# GT32U2086 register map
Vendor: FPTTelecom
Registers are 32-bit, read-write, reset 0x0 unless marked. A register's access mark holds for its fields unless they carry their own. Offsets are from the block's base; [hi:lo] are bit positions.

## SPI0 — SPI0 - DTI SPI rev1.1, Register Description chapter 9. SPI0 : 0x440C0000 - 0x440CFFFF (64 KB)
Base 0x440C0000
Same registers: SPI1 0x50090000
0x00 TX — Transmit Register bit[31:0] DATA
  [31:0] DATA — Transmit data; the effective width is determined by CMDCONF.LEN in master mode
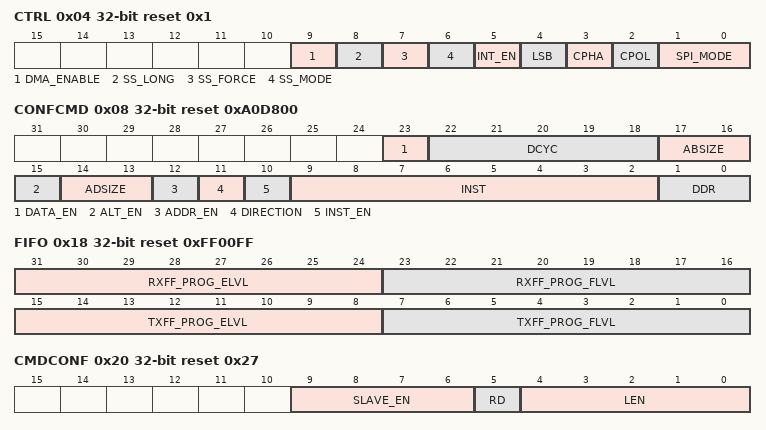
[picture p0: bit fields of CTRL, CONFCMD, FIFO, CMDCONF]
0x04 CTRL reset 0x1 — SPI Control Register bit[1:0] SPI_MODE | bit[2] CPOL | bit[3] CPHA | bit[4] LSB | bit[5] INT_EN | bit[6] SS_MODE | bit[7] SS_FORCE | bit[8] SS_LONG | bit[9] DMA_ENABLE
  [9] DMA_ENABLE — Globally enable the DMA interface (ctrl_dspi_modeable in rev1.1)
  [8] SS_LONG — Keep SS active until the TX FIFO is empty for long access sequences
  [7] SS_FORCE — In manual mode: 0=keep SS active, 1=allow SS release when conditions are met
  [6] SS_MODE — Master-mode SS control: 0=normal, 1=manual
  [5] INT_EN — Enable FIFO-status interrupt outputs
  [4] LSB — Bit order: 0=MSB first, 1=LSB first
  [3] CPHA — Clock phase: 0=sample on the first edge, 1=sample on the second edge
  [2] CPOL — SCLK idle level: 0=low, 1=high
  [1:0] SPI_MODE — 00=legacy slave, 01=legacy master, 10=extended DDR master; 11 reserved
0x08 CONFCMD reset 0xA0D800 — Extended DDR command configuration; unused in legacy SPI mode
  [23] DATA_EN — Enable data phase
  [22:18] DCYC — Extended-command dummy length, 0..31
  [17:16] ABSIZE — Alternate-byte size minus one byte, 0..3
  [15] ALT_EN — Enable alternate-byte phase
  [14:13] ADSIZE — Address size minus one byte, 0..3
  [12] ADDR_EN — Enable address phase
  [11] DIRECTION — 0=write, 1=read
  [10] INST_EN — Enable instruction phase
  [9:2] INST — Instruction byte
  [1:0] DDR — 00=SDR, 01=instruction SDR and remaining phases DDR, 11=DDR
0x0C DLR — Extended-mode data length register
  [31:0] DATA_LEN — Number of data bytes to send or receive
0x10 AR — Extended-mode command address register
  [31:0] ADDR — Command address
0x14 ABR — Extended-mode alternate-byte register
  [31:0] ALT_BYTE — Alternate-byte data
0x18 FIFO reset 0xFF00FF — FIFO Control Register bit[7:0] TXFF_PROG_FLVL | bit[15:8] TXFF_PROG_ELVL | bit[23:16] RXFF_PROG_FLVL | bit[31:24] RXFF_PROG_ELVL
  [31:24] RXFF_PROG_ELVL — Programmable RX FIFO empty threshold
  [23:16] RXFF_PROG_FLVL — Programmable RX FIFO full threshold
  [15:8] TXFF_PROG_ELVL — Programmable TX FIFO empty threshold
  [7:0] TXFF_PROG_FLVL — Programmable TX FIFO full threshold
0x1C CLK — Clock Register bit[15:0] DIV
  [15:0] DIV — SCLK period = 2 x (DIV + 1) x core-clock period
0x20 CMDCONF reset 0x27 — Command Configuration Register bit[4:0] LEN | bit[5] RD | bit[9:6] SLAVE_EN
  [9:6] SLAVE_EN — Select SS0..SS3 as one-hot in master mode
  [5] RD — Master: 1=store MISO data in the RX FIFO, 0=discard received data
  [4:0] LEN — Frame length minus 1; only 7/15/23/31 are supported, corresponding to 8/16/24/32 bits
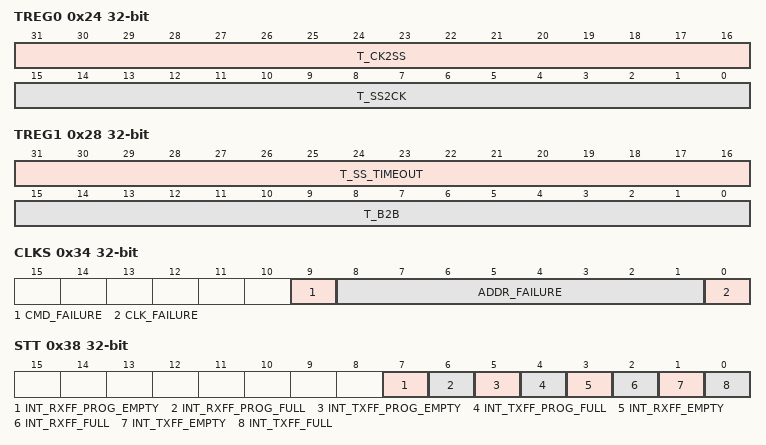
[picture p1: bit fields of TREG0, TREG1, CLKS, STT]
0x24 TREG0 — Timing Register 0 bit[15:0] T_SS2CK | bit[31:16] T_CK2SS
  [31:16] T_CK2SS — Number of cycles from stopping SCLK to SS deassertion
  [15:0] T_SS2CK — Number of cycles from SS assertion to SCLK generation
0x28 TREG1 — Timing Register 1 bit[15:0] T_B2B | bit[31:16] T_SS_TIMEOUT
  [31:16] T_SS_TIMEOUT — SS-active hold timeout; 0=disable the timeout function
  [15:0] T_B2B — Delay between data bytes in core-clock cycles, including bytes within a 16/24/32-bit word
0x2C TREG2 — Extended-mode timing register 2
  [15:0] T_CMD2CMD — Delay between extended DDR commands in core-clock cycles
0x30 RX ro — Receive Register bit[31:0] DATA
  [31:0] DATA — Receive data; the effective width is determined by CMDCONF.LEN in master mode
0x34 CLKS ro — Clock Status Register bit[0] CLK_FAILURE | bit[8:1] ADDR_FAILURE | bit[9] CMD_FAILURE
  [9] CMD_FAILURE — Failed command type: 0=write, 1=read
  [8:1] ADDR_FAILURE — Address of the first APB command affected by the clock failure
  [0] CLK_FAILURE — Core-clock stoppage detected
0x38 STT ro — Status Register bit[0] INT_TXFF_FULL | bit[1] INT_TXFF_EMPTY | bit[2] INT_RXFF_FULL | bit[3] INT_RXFF_EMPTY | bit[4] INT_TXFF_PROG_FULL | bit[5] INT_TXFF_PROG_EMPTY | bit[6] INT_RXFF_PROG_FULL | bit[7] INT_RXFF_PROG_EMPTY
  [7] INT_RXFF_PROG_EMPTY — RX FIFO reached the programmable-empty threshold
  [6] INT_RXFF_PROG_FULL — RX FIFO reached the programmable-full threshold
  [5] INT_TXFF_PROG_EMPTY — TX FIFO reached the programmable-empty threshold
  [4] INT_TXFF_PROG_FULL — TX FIFO reached the programmable-full threshold
  [3] INT_RXFF_EMPTY — RX FIFO empty
  [2] INT_RXFF_FULL — RX FIFO full
  [1] INT_TXFF_EMPTY — TX FIFO empty
  [0] INT_TXFF_FULL — TX FIFO full
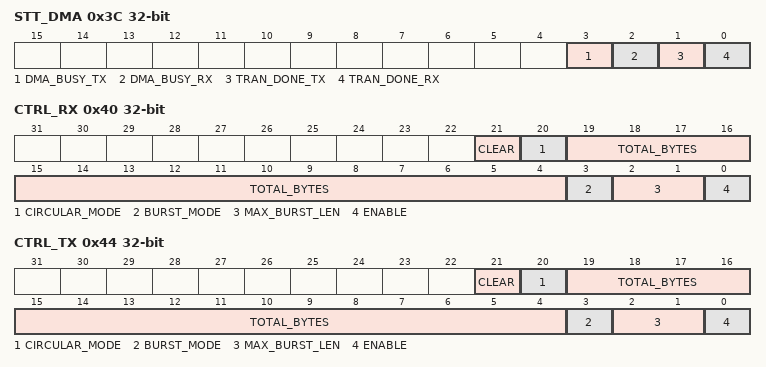
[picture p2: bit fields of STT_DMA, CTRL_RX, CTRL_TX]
0x3C STT_DMA ro — DMA Status Register bit[0] TRAN_DONE_RX | bit[1] TRAN_DONE_TX | bit[2] DMA_BUSY_RX | bit[3] DMA_BUSY_TX
  [3] DMA_BUSY_TX — Circular TX reconfiguration readiness: 1=allowed, 0=not yet allowed
  [2] DMA_BUSY_RX — Circular RX reconfiguration readiness: 1=allowed, 0=not yet allowed
  [1] TRAN_DONE_TX — DMA TX flag: 0=incomplete, 1=complete
  [0] TRAN_DONE_RX — DMA RX flag: 0=incomplete, 1=complete
0x40 CTRL_RX — DMA RX Control Register bit[0] ENABLE | bit[2:1] MAX_BURST_LEN | bit[3] BURST_MODE | bit[19:4] TOTAL_BYTES | bit[20] CIRCULAR_MODE | bit[21] CLEAR
  [21] CLEAR — Clear transfer-complete state and rearm one-shot configuration
  [20] CIRCULAR_MODE — 0=one-shot transfer, 1=continuous transfers
  [19:4] TOTAL_BYTES — Total DMA RX bytes; DTI requires a multiple of 4
  [3] BURST_MODE — 0=SINGLE only, 1=BURST
  [2:1] MAX_BURST_LEN — Singles-per-burst code: 0/1/2/3 correspond to 2/4/8/16
  [0] ENABLE — Enable the DMA RX channel
0x44 CTRL_TX — DMA TX Control Register bit[0] ENABLE | bit[2:1] MAX_BURST_LEN | bit[3] BURST_MODE | bit[19:4] TOTAL_BYTES | bit[20] CIRCULAR_MODE | bit[21] CLEAR
  [21] CLEAR — Clear transfer-complete state and rearm one-shot configuration
  [20] CIRCULAR_MODE — 0=one-shot transfer, 1=continuous transfers
  [19:4] TOTAL_BYTES — Total DMA TX bytes; DTI requires a multiple of 4
  [3] BURST_MODE — 0=SINGLE only, 1=BURST
  [2:1] MAX_BURST_LEN — Singles-per-burst code: 0/1/2/3 correspond to 2/4/8/16
  [0] ENABLE — Enable the DMA TX channel
